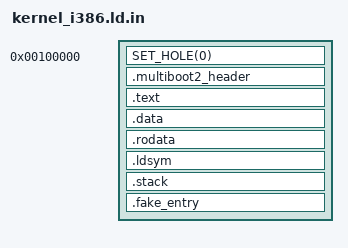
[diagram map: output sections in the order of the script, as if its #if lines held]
#include <ld/ldsym.h>
#include <ld/segment.h>
#include <ld/section.h>
#include <config.h>

ENTRY(_start)

SECTIONS
{
	. = 1M;
	SET_HOLE(0)

	__kernel_image_start_lma = .;
	__kernel_image_start_vma = .;

	DEFINE_SEGMENT (
		i386_text,
		DEFINE_SECTION (
			multiboot2_header,
			.multiboot2_header :
			{
				KEEP(*(.multiboot2_header))
			}
		)

		. += 1; /* Avoiding some stupid bug in linker or something I don't understand.
			 Without this .multiboot2_header and .text sections appear to start
			 at the same address besides they are both non-empty sections. */

		DEFINE_SECTION (
			i386_text,
			.text : ALIGN(16)
			{
				*(.text_entry)
				*(.text)
				*(.text.*)
			}
		)
	)

	DEFINE_SEGMENT (
		i386_data,
		DEFINE_SECTION (
			i386_data,
			.data :
			{
				*(.data)
			}
		)
	)

	DEFINE_SEGMENT (
		i386_rodata,
		DEFINE_SECTION (
			i386_rodata,
			.rodata :
			{
				*(.rodata)
				*(.rodata.*)
			}
		)

		DEFINE_SECTION (
			ldsym,
			.ldsym :
			{
				DEFINE_LDSYM(kernel_stack_top)
				DEFINE_LDSYM(kernel_image_start_vma)
				DEFINE_LDSYM(kernel_image_start_lma)
				DEFINE_LDSYM(kernel_image_end_vma)
				DEFINE_LDSYM(kernel_image_end_lma)

				DEFINE_SEGMENT_LDSYMS(stack)

#if CONFIG_ARCH == ARCH_x86_64
				DEFINE_SEGMENT_LDSYMS_NULL(x86_64_text)
				DEFINE_SEGMENT_LDSYMS_NULL(x86_64_rodata)
				DEFINE_SEGMENT_LDSYMS_NULL(x86_64_data)

				DEFINE_LDSYM_CUSTOM(kernel_x86_64_entry, __fake_entry)
#endif

				DEFINE_SEGMENT_LDSYMS_NULL(text)
				DEFINE_SEGMENT_LDSYMS_NULL(rodata)
				DEFINE_SEGMENT_LDSYMS_NULL(data)

				DEFINE_LDSYM_CUSTOM(kernel_main, __fake_entry)
			}
		)
	)

	DEFINE_SEGMENT (
		stack,
		DEFINE_SECTION (
			stack,
			.stack (NOLOAD) : ALIGN(CONFIG_STACK_ALIGNMENT)
			{
				. += CONFIG_STACK_SIZE;
			}
		)
	)

	PROVIDE(__kernel_stack_top = .);

	PROVIDE(__fake_entry = .);
	.fake_entry :
	{
		KEEP(*(.fake_entry))
	}
	PROVIDE(__fake_entry_size = . - __fake_entry);

	__kernel_image_end_vma = .;
	__kernel_image_end_lma = .;

	/DISCARD/ :
	{
		*(.bss) /* .bss won't be used in i386-specific code. */
		*(.note.*)
		*(.comment)
		*(.eh_frame)
	}
}
